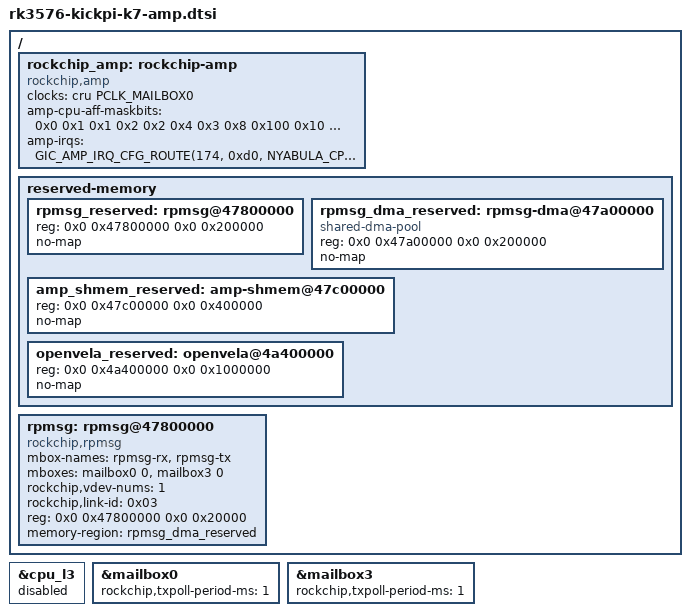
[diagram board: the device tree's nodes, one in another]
// SPDX-License-Identifier: (GPL-2.0+ OR MIT)
/*
 * KICKPI-K7 Linux side of the Nyabula CPU3 AMP deployment.
 *
 * Include this file after the normal board DTS.  N-Boot loads the openvela
 * image at 0x4a400000 and starts CPU3; Linux must never online that CPU.
 */

#include <dt-bindings/soc/rockchip-amp.h>

#define NYABULA_CPU_AFFINITY(cpu, cluster) (((cpu) << 0) | ((cluster) << 8))

/ {
	rockchip_amp: rockchip-amp {
		compatible = "rockchip,amp";
		clocks = <&cru PCLK_MAILBOX0>;

		amp-cpu-aff-maskbits = /bits/ 64 <
			0x0 0x1 0x1 0x2 0x2 0x4 0x3 0x8
			0x100 0x10 0x101 0x20 0x102 0x40 0x103 0x80>;
		amp-irqs = /bits/ 64 <
			GIC_AMP_IRQ_CFG_ROUTE(174, 0xd0,
				NYABULA_CPU_AFFINITY(3, 0))>;
		status = "okay";
	};

	reserved-memory {
		#address-cells = <2>;
		#size-cells = <2>;
		ranges;

		rpmsg_reserved: rpmsg@47800000 {
			reg = <0x0 0x47800000 0x0 0x200000>;
			no-map;
		};

		rpmsg_dma_reserved: rpmsg-dma@47a00000 {
			compatible = "shared-dma-pool";
			reg = <0x0 0x47a00000 0x0 0x200000>;
			no-map;
		};

		amp_shmem_reserved: amp-shmem@47c00000 {
			reg = <0x0 0x47c00000 0x0 0x400000>;
			no-map;
		};

		openvela_reserved: openvela@4a400000 {
			reg = <0x0 0x4a400000 0x0 0x1000000>;
			no-map;
		};
	};

	rpmsg: rpmsg@47800000 {
		compatible = "rockchip,rpmsg";
		mbox-names = "rpmsg-rx", "rpmsg-tx";
		mboxes = <&mailbox0 0 &mailbox3 0>;
		rockchip,vdev-nums = <1>;
		rockchip,link-id = <0x03>;
		reg = <0x0 0x47800000 0x0 0x20000>;
		memory-region = <&rpmsg_dma_reserved>;
		status = "okay";
	};
};

&cpu_l3 {
	status = "disabled";
};

&mailbox0 {
	rockchip,txpoll-period-ms = <1>;
	status = "okay";
};

&mailbox3 {
	rockchip,txpoll-period-ms = <1>;
	status = "okay";
};
